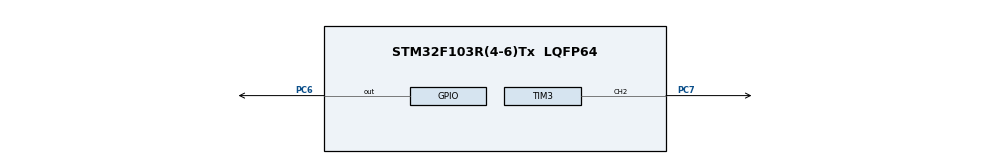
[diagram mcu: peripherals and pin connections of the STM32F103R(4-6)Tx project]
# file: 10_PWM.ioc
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Mcu.Family=STM32F1
Mcu.Name=STM32F103R(4-6)Tx
Mcu.Package=LQFP64
NVIC.PriorityGroup=NVIC_PRIORITYGROUP_4
PC6.Signal=GPIO_Output
PC7.Signal=S_TIM3_CH2
ProjectManager.HeapSize=0x200
ProjectManager.StackSize=0x400
ProjectManager.TargetToolchain=MDK-ARM V5.32
RCC.APB1Freq_Value=8000000
RCC.APB2Freq_Value=8000000
SH.S_TIM3_CH2.0=TIM3_CH2,PWM Generation2 CH2
TIM3.Channel-PWM\ Generation2\ CH2=TIM_CHANNEL_2
TIM3.OCPolarity_2=TIM_OCPOLARITY_LOW
TIM3.Period=99
TIM3.Prescaler=79
VP_SYS_VS_ND.Mode=No_Debug
VP_TIM3_VS_ClockSourceINT.Mode=Internal
board=custom

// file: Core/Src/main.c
/* USER CODE BEGIN Header */
/**
  ******************************************************************************
  * @file           : main.c
  * @brief          : Main program body
  ******************************************************************************
  * @attention
  *
  * Copyright (c) 2022 STMicroelectronics.
  * All rights reserved.
  *
  * This software is licensed under terms that can be found in the LICENSE file
  * in the root directory of this software component.
  * If no LICENSE file comes with this software, it is provided AS-IS.
  *
  ******************************************************************************
  */
/* USER CODE END Header */
#include "main.h"
#include "tim.h"
#include "gpio.h"

void SystemClock_Config(void);

int main(void)
{

  /* MCU Configuration--------------------------------------------------------*/

  /* Reset of all peripherals, Initializes the Flash interface and the Systick. */
  HAL_Init();

  /* Configure the system clock */
  SystemClock_Config();

  /* Initialize all configured peripherals */
  MX_GPIO_Init();
  MX_TIM3_Init();
  /* USER CODE BEGIN 2 */
	HAL_TIM_PWM_Start(&htim3, TIM_CHANNEL_2);  //定时器2运行并在通道2输出PWM函数
  /* USER CODE END 2 */

  /* Infinite loop */
  /* USER CODE BEGIN WHILE */
  while (1)
  {
		uint8_t i;  //循环变量
		for(i=0; i<=100; i+=4)  //一次循环时间  100/4*20ms = 500ms  渐弱
		{
			__HAL_TIM_SET_COMPARE(&htim3, TIM_CHANNEL_2, i);  //赋予定时器TIM3的CRR2寄存器的值为i
			HAL_Delay(20);
		}
		for(i=100; i>=0; i-=4)  //一次循环时间  100/4*20ms = 500ms  渐强
		{
			__HAL_TIM_SET_COMPARE(&htim3, TIM_CHANNEL_2, i);  //赋予定时器TIM3的CRR2寄存器的值为i
			HAL_Delay(20);
		}
    /* USER CODE END WHILE */

  }
}

void SystemClock_Config(void)
{
  RCC_OscInitTypeDef RCC_OscInitStruct = {0};
  RCC_ClkInitTypeDef RCC_ClkInitStruct = {0};

  /** Initializes the RCC Oscillators according to the specified parameters
  * in the RCC_OscInitTypeDef structure.
  */
  RCC_OscInitStruct.OscillatorType = RCC_OSCILLATORTYPE_HSI;
  RCC_OscInitStruct.HSIState = RCC_HSI_ON;
  RCC_OscInitStruct.HSICalibrationValue = RCC_HSICALIBRATION_DEFAULT;
  RCC_OscInitStruct.PLL.PLLState = RCC_PLL_NONE;
  if (HAL_RCC_OscConfig(&RCC_OscInitStruct) != HAL_OK)
  {
    Error_Handler();
  }

  /** Initializes the CPU, AHB and APB buses clocks
  */
  RCC_ClkInitStruct.ClockType = RCC_CLOCKTYPE_HCLK|RCC_CLOCKTYPE_SYSCLK
                              |RCC_CLOCKTYPE_PCLK1|RCC_CLOCKTYPE_PCLK2;
  RCC_ClkInitStruct.SYSCLKSource = RCC_SYSCLKSOURCE_HSI;
  RCC_ClkInitStruct.AHBCLKDivider = RCC_SYSCLK_DIV1;
  RCC_ClkInitStruct.APB1CLKDivider = RCC_HCLK_DIV1;
  RCC_ClkInitStruct.APB2CLKDivider = RCC_HCLK_DIV1;

  if (HAL_RCC_ClockConfig(&RCC_ClkInitStruct, FLASH_LATENCY_0) != HAL_OK)
  {
    Error_Handler();
  }
}

void Error_Handler(void)
{
  __disable_irq();
  while (1)
  {
  }
}
